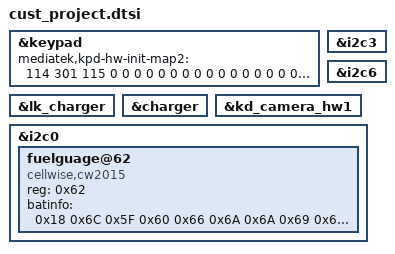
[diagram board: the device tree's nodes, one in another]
//add by lipengpeng 20210223 start
&keypad {
       mediatek,kpd-hw-init-map2 = <114 301 115 0 0 0 0 0 0 0
    0 0 0 0 0 0 0 0 0
    0 0 0 0 0 0 0 0 0
    0 0 0 0 0 0 0 0 0
    0 0 0 0 0 0 0 0 0
    0 0 0 0 0 0 0 0 0
    0 0 0 0 0 0 0 0 0
    0 0 0 0 0 0 0 0 >;

};
//add by lipengpeng 20210223 end

&lk_charger{
	//ac_charger_current = <3200000>;
	//ac_charger_input_current = <3000000>;
};

&charger{
	//ac_charger_current = <3200000>;
	//ac_charger_input_current = <3000000>;
};


&i2c3 {
//	spc@21 {
//		compatible = "prize,spc_r";
//		status = "disable";
//	};
};

&i2c6 {
//	spc_f@21 {
//		compatible = "prize,spc_r_1";
//		status = "disable";
//	};
};

&kd_camera_hw1 {
	//cam2_enable_sensor = "imx350_mipi_raw imx386_mipi_mono";//prize
};

&i2c0 {
	fuelguage@62 {
		compatible = "cellwise,cw2015";
		reg = <0x62>;
		batinfo = /bits/ 8 <0x18 0x6C 0x5F 0x60 0x66 0x6A 0x6A 0x69 0x66 0x63 0x5F 0x5E 0x6D 0x5E 0x4B 0x45
							0x40 0x38 0x31 0x2F 0x34 0x3B 0x44 0x51 0x24 0x55 0x0B 0x85 0x38 0x58 0x51 0x63
							0x74 0x69 0x69 0x69 0x3E 0x1A 0x76 0x68 0x0D 0x55 0x22 0x4E 0x89 0x94 0x9B 0x37
							0x55 0x6A 0x9A 0xB2 0x80 0xC0 0xEB 0xCB 0x2F 0x00 0x64 0xA5 0xB5 0xC1 0x46 0xAE>;
	};
};
